AUTOSAR XML (schema 314)
package /ComponentType
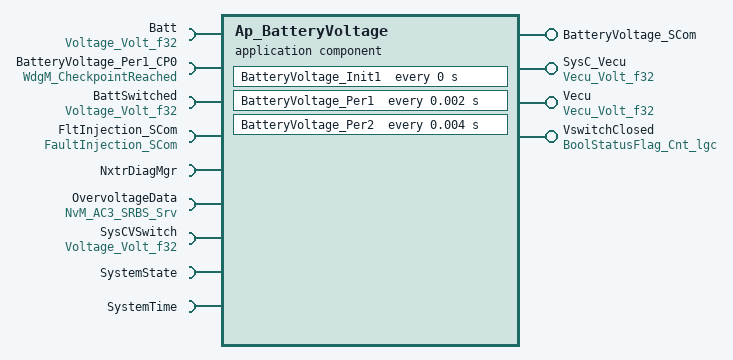
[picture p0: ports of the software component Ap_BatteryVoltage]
  application software component type Ap_BatteryVoltage
    4 x provide port:
      BatteryVoltage_SCom: provided-com-specs=[{operation=ClearTransOvData, queue-length=1}, {operation=ReadTransOvData, queue-length=1}], provided-interface=BatteryVoltage_SCom
      SysC_Vecu: unqueued-sender-com-spec{data-element=Volt_f32, can-invalidate=false, init-value=D_VECUMIN_VOLTS_F32}, provided-interface=Vecu_Volt_f32
      Vecu: unqueued-sender-com-spec{data-element=Volt_f32, can-invalidate=false, init-value=D_VECUMIN_VOLTS_F32}, provided-interface=Vecu_Volt_f32
      VswitchClosed: unqueued-sender-com-spec{data-element=Cnt_lgc, can-invalidate=false, init-value=D_FALSE_CNT_LGC}, provided-interface=BoolStatusFlag_Cnt_lgc
    9 x require port:
      Batt: unqueued-receiver-com-spec{data-element=Volt_f32, init-value=D_ZERO_ULS_F32}, required-interface=Voltage_Volt_f32
      BatteryVoltage_Per1_CP0: client-com-spec=CheckpointReached, required-interface=WdgM_CheckpointReached
      BattSwitched: unqueued-receiver-com-spec{data-element=Volt_f32, init-value=D_ZERO_ULS_F32}, required-interface=Voltage_Volt_f32
      FltInjection_SCom: client-com-spec=FltInjection, required-interface=FaultInjection_SCom
      NxtrDiagMgr: required-com-specs=[GetNTCActive, GetNTCFailed, GetNTCStatus, SetNTCStatus], required-interface=NxtrDiagMgr
      OvervoltageData: required-com-specs=[EraseBlock, GetErrorStatus, InvalidateNvBlock, ReadBlock, SetRamBlockStatus, WriteBlock], required-interface=NvM_AC3_SRBS_Srv
      SysCVSwitch: unqueued-receiver-com-spec{data-element=Volt_f32, init-value=D_ZERO_ULS_F32}, required-interface=Voltage_Volt_f32
      SystemState: required-interface=SystemState
      SystemTime: required-interface=SystemTime
        required-com-specs:
          DtrmnElapsedTime_mS_u16
          DtrmnElapsedTime_mS_u32
          DtrmnElapsedTime_uS_u16
          DtrmnElapsedTime_uS_u32
          GetSystemTime_mS_u32
          GetSystemTime_uS_u32
  internal behavior Ap_BatteryVoltage_InternalBehavior: component=Ap_BatteryVoltage
    timing event BatteryVoltage_Init1_InitEvent: start-on-event=BatteryVoltage_Init1, period=0
    timing event TMT_BatteryVoltage_Per1: start-on-event=BatteryVoltage_Per1, period=0.002
    timing event TMT_BatteryVoltage_Per2: mode-dependency=dependent-on-mode=[SystemState.Mode.DISABLE, SystemState.Mode.OFF, SystemState.Mode.WARMINIT], start-on-event=BatteryVoltage_Per2, period=0.004
    operation invoked event OIT_BatteryVoltage_SCom_ClearTransOvData_BatteryVoltage_SCom_ClearTransOvData: start-on-event=BatteryVoltage_SCom_ClearTransOvData, operation=BatteryVoltage_SCom.ClearTransOvData
    operation invoked event OIT_BatteryVoltage_SCom_ReadTransOvData_BatteryVoltage_SCom_ReadTransOvData: start-on-event=BatteryVoltage_SCom_ReadTransOvData, operation=BatteryVoltage_SCom.ReadTransOvData
    per instance memory OvervoltageData: type=OvervoltageDataType, type-definition=/DataType/OvervoltageDataType
    port-api-options:
      enable-take-address=false, indirect-api=false, port=Batt
      enable-take-address=false, indirect-api=false, port=BatteryVoltage_Per1_CP0
      enable-take-address=false, indirect-api=false, port=BatteryVoltage_SCom
      enable-take-address=false, indirect-api=false, port=BattSwitched
      enable-take-address=false, indirect-api=false, port=FltInjection_SCom
      enable-take-address=false, indirect-api=false, port=NxtrDiagMgr
      enable-take-address=false, indirect-api=false, port=OvervoltageData
      enable-take-address=false, indirect-api=false, port=SysC_Vecu
      enable-take-address=false, indirect-api=false, port=SysCVSwitch
      enable-take-address=false, indirect-api=false, port=SystemState
      enable-take-address=false, indirect-api=false, port=SystemTime
      enable-take-address=false, indirect-api=false, port=Vecu
      enable-take-address=false, indirect-api=false, port=VswitchClosed
    5 x runnable:
      BatteryVoltage_Init1
        sync call SC_NxtrDiagMgr_SetNTCStatus: operation=NxtrDiagMgr.SetNTCStatus, timeout=0
      BatteryVoltage_Per1
        data read access READ_Batt_Volt_f32: data-element=Batt.Volt_f32
        data read access READ_BattSwitched_Volt_f32: data-element=BattSwitched.Volt_f32
        data write access WRITE_SysC_Vecu_Volt_f32: data-element=SysC_Vecu.Volt_f32
        data write access WRITE_Vecu_Volt_f32: data-element=Vecu.Volt_f32
        data write access WRITE_VswitchClosed_Cnt_lgc: data-element=VswitchClosed.Cnt_lgc
        sync call SC_BatteryVoltage_Per1_CP0_CheckpointReached: operation=BatteryVoltage_Per1_CP0.CheckpointReached, timeout=0
        sync call SC_FltInjection_SCom_FltInjection: operation=FltInjection_SCom.FltInjection, timeout=0
      BatteryVoltage_Per2
        data read access READ_BattSwitched_Volt_f32: data-element=BattSwitched.Volt_f32
        data read access READ_SysCVSwitch_Volt_f32: data-element=SysCVSwitch.Volt_f32
        sync call SC_NxtrDiagMgr_SetNTCStatus: operation=NxtrDiagMgr.SetNTCStatus, timeout=0
      BatteryVoltage_SCom_ClearTransOvData
        sync call SC_OvervoltageData_SetRamBlockStatus: operation=OvervoltageData.SetRamBlockStatus, timeout=0
        sync call SC_OvervoltageData_WriteBlock: operation=OvervoltageData.WriteBlock, timeout=0
      BatteryVoltage_SCom_ReadTransOvData
    service-needss:
      swc nv block needs OvervoltageBlock: n-data-sets=0, readonly=false, reliability=LOW, resistant-to-changed-sw=false, restore-at-start=false, write-only-once=false, writing-frequency=0, writing-priority=LOW, mirror-block=OvervoltageData
  swc implementation Ap_BatteryVoltage_Implementation: behavior=Ap_BatteryVoltage_InternalBehavior
    code-descriptors:
      code Code: type=SRC
